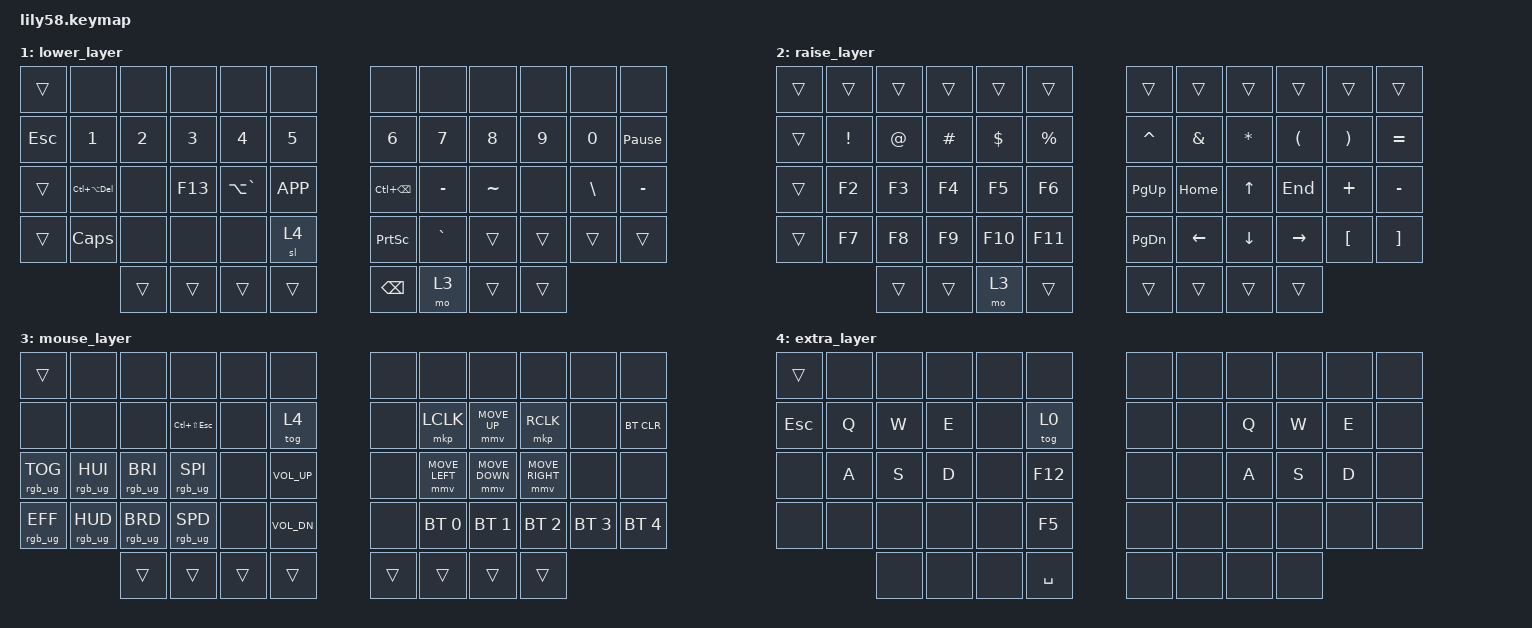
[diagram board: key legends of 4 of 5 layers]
/*
 * Copyright (c) 2020 The ZMK Contributors
 *
 * SPDX-License-Identifier: MIT
 */

#include <behaviors.dtsi>
#include <dt-bindings/zmk/keys.h>
#include <dt-bindings/zmk/bt.h>
#include <dt-bindings/zmk/ext_power.h>
#include <dt-bindings/zmk/rgb.h>
#include <dt-bindings/zmk/mouse.h>
#include <dt-bindings/led/led.h> /* bodo you need this to turn on ARGEEBEEH nowadays weh */

#define DEFAULT 0-base
#define LOWER   1-numbers
#define RAISE   2-symbols
#define ADJUST  3-misc-rgb-bt
#define GAMING  4-extra

&spi1 {
  compatible = "nordic,nrf-spim";
  status = "okay";
  mosi-pin = <6>; /* 6 = D1 or P0.06. 20 = D3 or P0.20 . in case it doesnt work*/
  // Unused pins, needed for SPI definition, but not used by the ws2812 driver itself.
  sck-pin = <5>;
  miso-pin = <7>;

  led_strip: ws2812@0 {
    compatible = "worldsemi,ws2812-spi";
    label = "WS2812";

    /* SPI */
    reg = <0>; /* ignored, but necessary for SPI bindings */
    spi-max-frequency = <4000000>;

    /* WS2812 */
    chain-length = <14>; /* number of LEDs << 14 each side*/
    spi-one-frame = <0x70>;
    spi-zero-frame = <0x40>;
    color-mapping = <LED_COLOR_ID_GREEN
                          LED_COLOR_ID_RED
                          LED_COLOR_ID_BLUE>;
  };
};

/ {
   chosen {
      zmk,underglow = &led_strip;
   };
};

&mmv {
    time-to-max-speed-ms = <500>;
    acceleration-exponent = <0>;
};

&mwh {
    acceleration-exponent=<1>;
};

&mt {
    tapping-term-ms = <200>;
};

&lt {
    tapping-term-ms = <200>;
};


/ {
	keymap {
		compatible = "zmk,keymap";

		default_layer {

			bindings = <
&kp C_MUTE  &none &none &none  &none  &none                			&none  &none &none &none  &kp F5  &none
&kp TAB     &kp Q   &kp W   &kp F   &kp P   &kp B                   		&kp J   &kp L   &kp U   &kp Y  &kp SEMI  &kp DEL
&kp LGUI &kp A  &kp R  &kp S    &kp T    &kp G                      		&kp M  &kp N    &kp E     &kp I   &kp O &kp SQT
&kp LSHFT &mt LALT Z  &kp X  &kp C    &kp D    &kp V  &kp LBKT   &kp RBKT 	&kp K  &kp H    &kp COMMA &kp DOT &kp FSLH &kp ENTER
                       &none &kp LCTRL &mo 1  &kp SPACE  &kp BSPC  &mo 2  &kp LALT &none
			>;
			sensor-bindings = <&inc_dec_kp C_VOL_UP C_VOL_DN>;
		};

		lower_layer {
		
			bindings = <
&trans  &none &none &none  &none  &none                          		&none  &none &none &none  &none  &none
&kp ESC &kp N1  &kp N2  &kp N3  &kp N4  &kp N5                        &kp N6  &kp N7  &kp N8  &kp N9  &kp N0  &kp PAUSE_BREAK
&trans  &kp LC(LA(DEL))   &none  &kp F13 &kp LA(GRAVE) &kp K_APP      &kp LC(BSPC)    &kp MINUS   &kp TILDE   &none  &kp BSLH    &kp MINUS
&trans  &kp CAPS &none &none  &none  &sl 4 	                          &kp PSCRN &kp GRAVE &trans &trans &trans &trans
                        &trans &trans &trans &trans  &kp BSPC    &mo 3 &trans &trans
			>;

			sensor-bindings = <&inc_dec_kp C_VOL_UP C_VOL_DN>;
		};

		raise_layer {

			bindings = <
&trans    &trans &trans &trans  &trans  &trans                       &trans      &trans    &trans    &trans   &trans    &trans
&trans     &kp EXCL &kp AT &kp POUND &kp DLLR  &kp PRCNT    &kp CARET  &kp AMPS    &kp ASTRK    &kp LPAR   &kp RPAR   &kp EQUAL
&trans   &kp F2 &kp F3 &kp F4  &kp F5  &kp F6               &kp PG_UP  &kp HOME  &kp UP &kp END   &kp PLUS &kp MINUS
&trans   &kp F7 &kp F8 &kp F9 &kp F10 &kp F11               &kp PG_DN &kp LEFT &kp DOWN &kp RIGHT &kp LBKT  &kp RBKT
                        &trans &trans &mo 3  &trans &trans &trans  &trans &trans 
			>;

			sensor-bindings = <&inc_dec_kp C_VOL_UP C_VOL_DN>;
		};
		
                mouse_layer {

// mouse keys here: https://github.com/ftc/zmk/blob/mouse-ftc/docs/docs/behaviors/mouse-emulation.md
                        bindings = <
&trans  &none &none &none  &none  &none                          		&none  &none &none &none  &none  &none			
&none            &none           &none           &kp LC(LS(ESC))  &none  &tog 4   	        &none  &mkp LCLK      &mmv MOVE_UP    &mkp RCLK        &none  &bt BT_CLR
&rgb_ug RGB_TOG  &rgb_ug RGB_HUI &rgb_ug RGB_BRI &rgb_ug RGB_SPI  &none  &kp C_VOL_UP       &none  &mmv MOVE_LEFT &mmv MOVE_DOWN  &mmv MOVE_RIGHT  &none  &none
&rgb_ug RGB_EFF  &rgb_ug RGB_HUD &rgb_ug RGB_BRD &rgb_ug RGB_SPD  &none  &kp C_VOL_DN       &none  &bt BT_SEL 0     &bt BT_SEL 1      &bt BT_SEL 2  &bt BT_SEL 3 &bt BT_SEL 4
                        &trans &trans &trans  &trans  &trans &trans &trans &trans
                        >;
                };

                extra_layer {

                        bindings = <
&trans  &none &none &none  &none  &none                          		&none  &none &none &none  &none  &none
&kp ESC &kp Q   &kp W   &kp E   &none   &tog 0     &none  &none   &kp Q  &kp W  &kp E  &none
&none   &kp A   &kp S   &kp D   &none   &kp F12    &none  &none   &kp A  &kp S  &kp D  &none
&none   &none   &none   &none   &none   &kp F5     &none  &none   &none  &none  &none  &none
                        &none &none  &none   &kp SPACE  &none   &none   &none &none                      
                        >;
                };		
		
	};
};
